# ATmega328P register map
File version: 1.0
Registers are 8-bit, read-write, reset 0x0 unless marked. A register's access mark holds for its fields unless they carry their own. Offsets are from the block's base; lines under a group give offsets from that group; [hi:lo] are bit positions; {n}, {i} and the like mark numbered series; 'fields as' and 'values as' point back to an identical list; <NAME> marks a mode.

## Memory map
0x00800000 USART0 — USART
0x00800000 TWI — Two Wire Serial Interface
0x00800000 TC1 — Timer/Counter, 16-bit
0x00800000 TC2 — Timer/Counter, 8-bit Async
0x00800000 ADC — Analog-to-Digital Converter
0x00800000 AC — Analog Comparator
0x00800000 PORTB — I/O Port
0x00800000 PORTC — I/O Port
0x00800000 PORTD — I/O Port
0x00800000 TC0 — Timer/Counter, 8-bit
0x00800000 EXINT — External Interrupts
0x00800000 SPI — Serial Peripheral Interface
0x00800000 WDT — Watchdog Timer
0x00800000 EEPROM

## USART0 — USART
Base 0x00800000
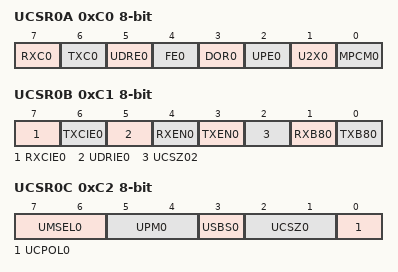
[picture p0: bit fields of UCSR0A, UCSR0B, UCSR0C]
0xC0 UCSR0A ro — USART Control and Status Register A
  [7] RXC0 — USART Receive Complete
  [6] TXC0 — USART Transmitt Complete
  [5] UDRE0 — USART Data Register Empty
  [4] FE0 — Framing Error
  [3] DOR0 — Data overRun
  [2] UPE0 — Parity Error
  [1] U2X0 — Double the USART transmission speed
  [0] MPCM0 — Multi-processor Communication Mode
0xC1 UCSR0B ro — USART Control and Status Register B
  [7] RXCIE0 — RX Complete Interrupt Enable
  [6] TXCIE0 — TX Complete Interrupt Enable
  [5] UDRIE0 — USART Data register Empty Interrupt Enable
  [4] RXEN0 — Receiver Enable
  [3] TXEN0 — Transmitter Enable
  [2] UCSZ02 — Character Size
  [1] RXB80 — Receive Data Bit 8
  [0] TXB80 — Transmit Data Bit 8
0xC2 UCSR0C ro — USART Control and Status Register C
  [7:6] UMSEL0 — USART Mode Select
  [5:4] UPM0 — Parity Mode Bits
  [3] USBS0 — Stop Bit Select
  [2:1] UCSZ0 — Character Size
  [0] UCPOL0 — Clock Polarity
0xC4 UBRR0 16-bit ro (reset mask 0xFF) — USART Baud Rate Register Bytes

## TWI — Two Wire Serial Interface
Base 0x00800000
0xB8 TWBR — TWI Bit Rate register
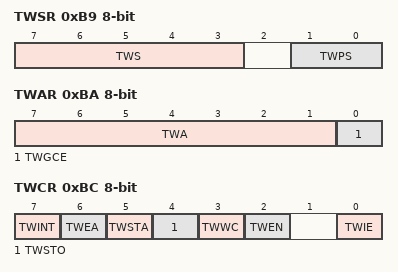
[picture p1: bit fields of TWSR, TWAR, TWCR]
0xB9 TWSR — TWI Status Register
  [7:3] TWS — TWI Status
  [1:0] TWPS — TWI Prescaler
0xBA TWAR — TWI (Slave) Address register
  [7:1] TWA — TWI (Slave) Address register Bits
  [0] TWGCE — TWI General Call Recognition Enable Bit
0xBB TWDR — TWI Data register
0xBC TWCR — TWI Control Register
  [7] TWINT — TWI Interrupt Flag
  [6] TWEA — TWI Enable Acknowledge Bit
  [5] TWSTA — TWI Start Condition Bit
  [4] TWSTO — TWI Stop Condition Bit
  [3] TWWC — TWI Write Collition Flag
  [2] TWEN — TWI Enable Bit
  [0] TWIE — TWI Interrupt Enable
0xBD TWAMR — TWI (Slave) Address Mask Register
  [7:1] TWAM

## TC1 — Timer/Counter, 16-bit
Base 0x00800000
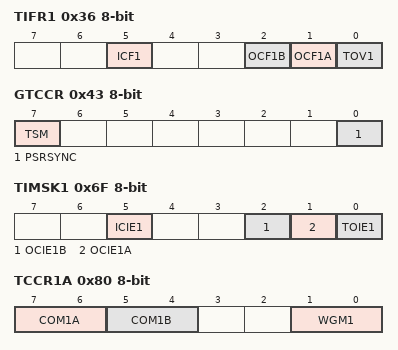
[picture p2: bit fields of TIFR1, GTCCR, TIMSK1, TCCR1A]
0x36 TIFR1 — Timer/Counter Interrupt Flag register
  [5] ICF1 — Input Capture Flag 1
  [2] OCF1B — Output Compare Flag 1B
  [1] OCF1A — Output Compare Flag 1A
  [0] TOV1 — Timer/Counter1 Overflow Flag
0x43 GTCCR — General Timer/Counter Control Register
  [7] TSM — Timer/Counter Synchronization Mode
  [0] PSRSYNC — Prescaler Reset Timer/Counter1 and Timer/Counter0
0x6F TIMSK1 — Timer/Counter Interrupt Mask Register
  [5] ICIE1 — Timer/Counter1 Input Capture Interrupt Enable
  [2] OCIE1B — Timer/Counter1 Output CompareB Match Interrupt Enable
  [1] OCIE1A — Timer/Counter1 Output CompareA Match Interrupt Enable
  [0] TOIE1 — Timer/Counter1 Overflow Interrupt Enable
0x80 TCCR1A — Timer/Counter1 Control Register A
  [7:6] COM1A — Compare Output Mode 1A, bits
  [5:4] COM1B — Compare Output Mode 1B, bits
  [1:0] WGM1 — Waveform Generation Mode
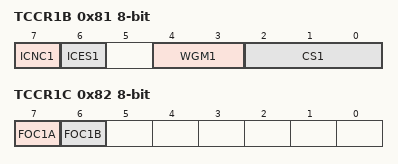
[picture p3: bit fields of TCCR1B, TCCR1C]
0x81 TCCR1B — Timer/Counter1 Control Register B
  [7] ICNC1 — Input Capture 1 Noise Canceler
  [6] ICES1 — Input Capture 1 Edge Select
  [4:3] WGM1 — Waveform Generation Mode
  [2:0] CS1 — Prescaler source of Timer/Counter 1
0x82 TCCR1C — Timer/Counter1 Control Register C
  [7] FOC1A, [6] FOC1B
0x84 TCNT1 16-bit (reset mask 0xFF) — Timer/Counter1 Bytes
0x86 ICR1 16-bit (reset mask 0xFF) — Timer/Counter1 Input Capture Register Bytes
0x88 OCR1A 16-bit (reset mask 0xFF) — Timer/Counter1 Output Compare Register Bytes
0x8A OCR1B 16-bit (reset mask 0xFF) — Timer/Counter1 Output Compare Register Bytes
